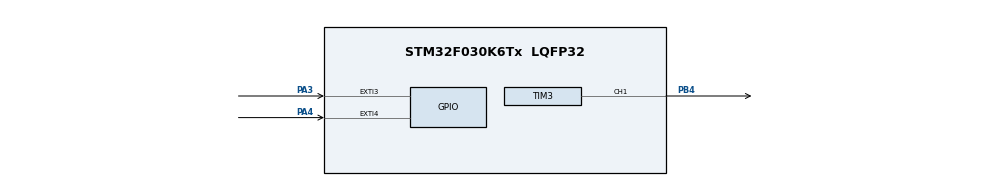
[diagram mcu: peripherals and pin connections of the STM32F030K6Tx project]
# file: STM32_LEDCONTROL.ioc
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Mcu.Family=STM32F0
Mcu.Name=STM32F030K6Tx
Mcu.Package=LQFP32
NVIC.EXTI2_3_IRQn=true\:0\:0\:false\:false\:true\:true\:true
NVIC.EXTI4_15_IRQn=true\:0\:0\:false\:false\:true\:true\:true
PA13.Mode=Serial_Wire
PA13.Signal=SYS_SWDIO
PA14.Mode=Serial_Wire
PA14.Signal=SYS_SWCLK
PA3.GPIO_ModeDefaultEXTI=GPIO_MODE_IT_FALLING
PA3.Signal=GPXTI3
PA4.GPIO_ModeDefaultEXTI=GPIO_MODE_IT_FALLING
PA4.Signal=GPXTI4
PB4.Signal=S_TIM3_CH1
ProjectManager.HeapSize=0x200
ProjectManager.StackSize=0x400
ProjectManager.TargetToolchain=MDK-ARM V5.27
RCC.AHBFreq_Value=48000000
RCC.APB1CLKDivider=RCC_HCLK_DIV2
RCC.APB1Freq_Value=24000000
RCC.APB1TimFreq_Value=48000000
RCC.FLatency=FLASH_LATENCY_1
RCC.HCLKFreq_Value=48000000
RCC.PLLMUL=RCC_PLL_MUL12
RCC.SYSCLKFreq_VALUE=48000000
RCC.SYSCLKSource=RCC_SYSCLKSOURCE_PLLCLK
SH.S_TIM3_CH1.0=TIM3_CH1,PWM Generation1 CH1
TIM3.AutoReloadPreload=TIM_AUTORELOAD_PRELOAD_ENABLE
TIM3.Channel-PWM\ Generation1\ CH1=TIM_CHANNEL_1
TIM3.Period=2399
board=custom

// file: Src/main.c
/* USER CODE BEGIN Header */
/**
  ******************************************************************************
  * @file           : main.c
  * @brief          : Main program body
  ******************************************************************************
  * @attention
  *
  * <h2><center>&copy; Copyright (c) 2020 STMicroelectronics.
  * All rights reserved.</center></h2>
  *
  * This software component is licensed by ST under BSD 3-Clause license,
  * the "License"; You may not use this file except in compliance with the
  * License. You may obtain a copy of the License at:
  *                        opensource.org/licenses/BSD-3-Clause
  *
  ******************************************************************************
  */
/* USER CODE END Header */

#include "main.h"

/* USER CODE BEGIN Includes */
#include "stdbool.h"
#include "STLib.h"
/* USER CODE END Includes */

/* USER CODE BEGIN PV */
uint16_t PWM = 0;
/* USER CODE END PV */

void SystemClock_Config(void);
static void MX_GPIO_Init(void);
static void MX_TIM3_Init(void);

int main(void)
{

  /* MCU Configuration--------------------------------------------------------*/

  /* Reset of all peripherals, Initializes the Flash interface and the Systick. */

  LL_APB1_GRP2_EnableClock(LL_APB1_GRP2_PERIPH_SYSCFG);
  LL_APB1_GRP1_EnableClock(LL_APB1_GRP1_PERIPH_PWR);

  /* System interrupt init*/

  /* Configure the system clock */
  SystemClock_Config();

  /* Initialize all configured peripherals */
  MX_GPIO_Init();
  MX_TIM3_Init();
  /* USER CODE BEGIN 2 */
	PWM = 0;
	//HAL_TIM_PWM_Start(&htim1, TIM_CHANNEL_1);

	//LL_TIM_OC_EnablePreload(TIM3, LL_TIM_CHANNEL_CH1);
	TIM3->CCMR1 |= TIM_CCMR1_OC1PE;
	TIM3->CCER |= TIM_CCER_CC1E;
	TIM3->CR1 |= TIM_CR1_CEN;
	//LL_TIM_EnableCounter(TIM1);

	SET_BIT(TIM3->CR1, TIM_CR1_CEN);
	//SET_BIT(TIM1->BDTR, TIM_BDTR_MOE);

  /* USER CODE END 2 */

  /* Infinite loop */
  while (1)
  {

  }
}

void SystemClock_Config(void)
{
  LL_FLASH_SetLatency(LL_FLASH_LATENCY_1);

  if(LL_FLASH_GetLatency() != LL_FLASH_LATENCY_1)
  {
  Error_Handler();
  }
  LL_RCC_HSI_Enable();

   /* Wait till HSI is ready */
  while(LL_RCC_HSI_IsReady() != 1)
  {

  }
  LL_RCC_HSI_SetCalibTrimming(16);
  LL_RCC_PLL_ConfigDomain_SYS(LL_RCC_PLLSOURCE_HSI_DIV_2, LL_RCC_PLL_MUL_12);
  LL_RCC_PLL_Enable();

   /* Wait till PLL is ready */
  while(LL_RCC_PLL_IsReady() != 1)
  {

  }
  LL_RCC_SetAHBPrescaler(LL_RCC_SYSCLK_DIV_1);
  LL_RCC_SetAPB1Prescaler(LL_RCC_APB1_DIV_2);
  LL_RCC_SetSysClkSource(LL_RCC_SYS_CLKSOURCE_PLL);

   /* Wait till System clock is ready */
  while(LL_RCC_GetSysClkSource() != LL_RCC_SYS_CLKSOURCE_STATUS_PLL)
  {

  }
  LL_Init1msTick(48000000);
  LL_SetSystemCoreClock(48000000);
}

static void MX_TIM3_Init(void)
{

  LL_TIM_InitTypeDef TIM_InitStruct = {0};
  LL_TIM_OC_InitTypeDef TIM_OC_InitStruct = {0};

  LL_GPIO_InitTypeDef GPIO_InitStruct = {0};

  /* Peripheral clock enable */
  LL_APB1_GRP1_EnableClock(LL_APB1_GRP1_PERIPH_TIM3);

  TIM_InitStruct.Prescaler = 0;
  TIM_InitStruct.CounterMode = LL_TIM_COUNTERMODE_UP;
  TIM_InitStruct.Autoreload = 2399;
  TIM_InitStruct.ClockDivision = LL_TIM_CLOCKDIVISION_DIV1;
  LL_TIM_Init(TIM3, &TIM_InitStruct);
  LL_TIM_EnableARRPreload(TIM3);
  LL_TIM_OC_EnablePreload(TIM3, LL_TIM_CHANNEL_CH1);
  TIM_OC_InitStruct.OCMode = LL_TIM_OCMODE_PWM1;
  TIM_OC_InitStruct.OCState = LL_TIM_OCSTATE_DISABLE;
  TIM_OC_InitStruct.OCNState = LL_TIM_OCSTATE_DISABLE;
  TIM_OC_InitStruct.CompareValue = 0;
  TIM_OC_InitStruct.OCPolarity = LL_TIM_OCPOLARITY_HIGH;
  LL_TIM_OC_Init(TIM3, LL_TIM_CHANNEL_CH1, &TIM_OC_InitStruct);
  LL_TIM_OC_DisableFast(TIM3, LL_TIM_CHANNEL_CH1);
  LL_TIM_SetTriggerOutput(TIM3, LL_TIM_TRGO_RESET);
  LL_TIM_DisableMasterSlaveMode(TIM3);
  LL_AHB1_GRP1_EnableClock(LL_AHB1_GRP1_PERIPH_GPIOB);
  /**TIM3 GPIO Configuration
  PB4   ------> TIM3_CH1
  */
  GPIO_InitStruct.Pin = LL_GPIO_PIN_4;
  GPIO_InitStruct.Mode = LL_GPIO_MODE_ALTERNATE;
  GPIO_InitStruct.Speed = LL_GPIO_SPEED_FREQ_LOW;
  GPIO_InitStruct.OutputType = LL_GPIO_OUTPUT_PUSHPULL;
  GPIO_InitStruct.Pull = LL_GPIO_PULL_NO;
  GPIO_InitStruct.Alternate = LL_GPIO_AF_1;
  LL_GPIO_Init(GPIOB, &GPIO_InitStruct);

}

static void MX_GPIO_Init(void)
{
  LL_EXTI_InitTypeDef EXTI_InitStruct = {0};

  /* GPIO Ports Clock Enable */
  LL_AHB1_GRP1_EnableClock(LL_AHB1_GRP1_PERIPH_GPIOA);
  LL_AHB1_GRP1_EnableClock(LL_AHB1_GRP1_PERIPH_GPIOB);

  /**/
  LL_SYSCFG_SetEXTISource(LL_SYSCFG_EXTI_PORTA, LL_SYSCFG_EXTI_LINE3);

  /**/
  LL_SYSCFG_SetEXTISource(LL_SYSCFG_EXTI_PORTA, LL_SYSCFG_EXTI_LINE4);

  /**/
  LL_GPIO_SetPinPull(GPIOA, LL_GPIO_PIN_3, LL_GPIO_PULL_NO);

  /**/
  LL_GPIO_SetPinPull(GPIOA, LL_GPIO_PIN_4, LL_GPIO_PULL_NO);

  /**/
  LL_GPIO_SetPinMode(GPIOA, LL_GPIO_PIN_3, LL_GPIO_MODE_INPUT);

  /**/
  LL_GPIO_SetPinMode(GPIOA, LL_GPIO_PIN_4, LL_GPIO_MODE_INPUT);

  /**/
  EXTI_InitStruct.Line_0_31 = LL_EXTI_LINE_3;
  EXTI_InitStruct.LineCommand = ENABLE;
  EXTI_InitStruct.Mode = LL_EXTI_MODE_IT;
  EXTI_InitStruct.Trigger = LL_EXTI_TRIGGER_FALLING;
  LL_EXTI_Init(&EXTI_InitStruct);

  /**/
  EXTI_InitStruct.Line_0_31 = LL_EXTI_LINE_4;
  EXTI_InitStruct.LineCommand = ENABLE;
  EXTI_InitStruct.Mode = LL_EXTI_MODE_IT;
  EXTI_InitStruct.Trigger = LL_EXTI_TRIGGER_FALLING;
  LL_EXTI_Init(&EXTI_InitStruct);

  /* EXTI interrupt init*/
  NVIC_SetPriority(EXTI2_3_IRQn, 0);
  NVIC_EnableIRQ(EXTI2_3_IRQn);
  NVIC_SetPriority(EXTI4_15_IRQn, 0);
  NVIC_EnableIRQ(EXTI4_15_IRQn);

}

void Error_Handler(void)
{
}

/************************ (C) COPYRIGHT STMicroelectronics *****END OF FILE****/
